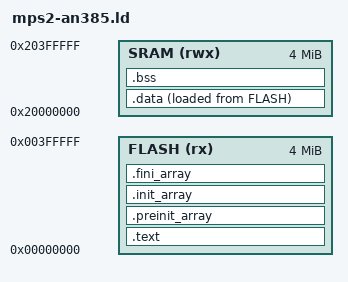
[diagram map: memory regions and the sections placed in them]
/* Linker script for the QEMU mps2-an385 (Cortex-M3) machine.
 *
 * Memory map:
 *   FLASH (boot ROM image): 0x00000000, 4 MiB — Cortex-M3 fetches initial SP
 *                           from address 0 and Reset_Handler from address 4.
 *   SRAM:                   0x20000000, 4 MiB — runtime data + heap + stack.
 */

ENTRY(Reset_Handler)

MEMORY
{
    FLASH (rx)  : ORIGIN = 0x00000000, LENGTH = 4M
    SRAM  (rwx) : ORIGIN = 0x20000000, LENGTH = 4M
}

_estack = ORIGIN(SRAM) + LENGTH(SRAM);

SECTIONS
{
    .text :
    {
        KEEP(*(.vectors))
        *(.text*)
        *(.rodata*)
        *(.glue_7) *(.glue_7t)
        KEEP(*(.init))
        KEEP(*(.fini))
        . = ALIGN(4);
        _etext = .;
    } > FLASH

    .preinit_array :
    {
        PROVIDE(__preinit_array_start = .);
        KEEP(*(.preinit_array))
        PROVIDE(__preinit_array_end = .);
    } > FLASH

    .init_array :
    {
        PROVIDE(__init_array_start = .);
        KEEP(*(SORT(.init_array.*)))
        KEEP(*(.init_array))
        PROVIDE(__init_array_end = .);
    } > FLASH

    .fini_array :
    {
        PROVIDE(__fini_array_start = .);
        KEEP(*(SORT(.fini_array.*)))
        KEEP(*(.fini_array))
        PROVIDE(__fini_array_end = .);
    } > FLASH

    .data :
    {
        . = ALIGN(4);
        _sdata = .;
        *(.data*)
        . = ALIGN(4);
        _edata = .;
    } > SRAM AT > FLASH

    _sidata = LOADADDR(.data);

    .bss :
    {
        . = ALIGN(4);
        _sbss = .;
        *(.bss*)
        *(COMMON)
        . = ALIGN(4);
        _ebss = .;
    } > SRAM

    /* newlib heap base. _sbrk grows _end upward toward the stack. */
    . = ALIGN(4);
    _end = .;
    PROVIDE(end = _end);
}
